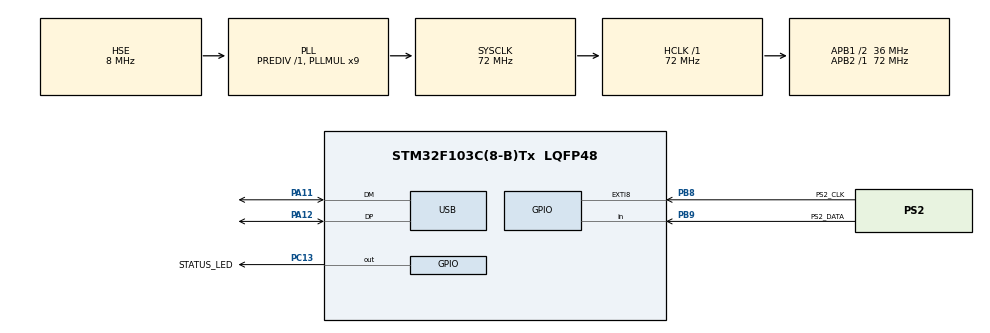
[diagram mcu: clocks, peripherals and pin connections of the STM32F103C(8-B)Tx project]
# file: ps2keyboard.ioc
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FREERTOS.Tasks01=defaultTask,0,128,StartDefaultTask,Default,NULL
FREERTOS.configUSE_COUNTING_SEMAPHORES=1
Mcu.Family=STM32F1
Mcu.Name=STM32F103C(8-B)Tx
Mcu.Package=LQFP48
NVIC.EXTI9_5_IRQn=true\:3\:0\:true\:false\:true\:false\:true
NVIC.PriorityGroup=NVIC_PRIORITYGROUP_4
NVIC.TIM1_UP_IRQn=true\:0\:0\:false\:false\:true\:false\:false
NVIC.TimeBase=TIM1_UP_IRQn
NVIC.TimeBaseIP=TIM1
NVIC.USB_LP_CAN1_RX0_IRQn=true\:5\:0\:false\:false\:true\:true\:false
PA11.Mode=Device
PA11.Signal=USB_DM
PA12.Mode=Device
PA12.Signal=USB_DP
PA13.Mode=Trace_Asynchronous_SW
PA13.Signal=SYS_JTMS-SWDIO
PA14.Mode=Trace_Asynchronous_SW
PA14.Signal=SYS_JTCK-SWCLK
PB3.Mode=Trace_Asynchronous_SW
PB3.Signal=SYS_JTDO-TRACESWO
PB8.GPIO_Label=PS2_CLK
PB8.GPIO_ModeDefaultEXTI=GPIO_MODE_IT_RISING
PB8.Signal=GPXTI8
PB9.GPIO_Label=PS2_DATA
PB9.Signal=GPIO_Input
PC13-TAMPER-RTC.GPIO_Label=STATUS_LED
PC13-TAMPER-RTC.Signal=GPIO_Output
PD0-OSC_IN.Mode=HSE-External-Oscillator
PD0-OSC_IN.Signal=RCC_OSC_IN
PD1-OSC_OUT.Mode=HSE-External-Oscillator
PD1-OSC_OUT.Signal=RCC_OSC_OUT
ProjectManager.HeapSize=0x200
ProjectManager.StackSize=0x400
ProjectManager.TargetToolchain=TrueSTUDIO
RCC.AHBFreq_Value=72000000
RCC.APB1CLKDivider=RCC_HCLK_DIV2
RCC.APB1Freq_Value=36000000
RCC.APB1TimFreq_Value=72000000
RCC.APB2Freq_Value=72000000
RCC.APB2TimFreq_Value=72000000
RCC.EnbaleCSS=true
RCC.HCLKFreq_Value=72000000
RCC.PLLMUL=RCC_PLL_MUL9
RCC.PLLSourceVirtual=RCC_PLLSOURCE_HSE
RCC.SYSCLKFreq_VALUE=72000000
RCC.SYSCLKSource=RCC_SYSCLKSOURCE_PLLCLK
RCC.USBFreq_Value=48000000
RCC.USBPrescaler=RCC_USBCLKSOURCE_PLL_DIV1_5
USB_DEVICE.CLASS_NAME_FS=CDC
USB_DEVICE.VirtualMode=Cdc
USB_DEVICE.VirtualModeFS=Cdc_FS
VP_FREERTOS_VS_ENABLE.Mode=Enabled
VP_SYS_VS_tim1.Mode=TIM1
VP_USB_DEVICE_VS_USB_DEVICE_CDC_FS.Mode=CDC_FS
board=ps2keyboard

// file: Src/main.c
/* USER CODE BEGIN Header */
/**
  * @brief  Function implementing the defaultTask thread.
  * @param  argument: Not used
  * @retval None
  */
/* USER CODE END Header */

#include "main.h"
#include "cmsis_os.h"
#include "usb_device.h"

/* USER CODE BEGIN Includes */
#include "tasks/startup.h"
/* USER CODE END Includes */

osThreadId defaultTaskHandle;
/* USER CODE BEGIN PV */
/* Private variables ---------------------------------------------------------*/

/* USER CODE END PV */

void SystemClock_Config(void);
static void MX_GPIO_Init(void);
void StartDefaultTask(void const * argument);

/* USER CODE BEGIN PFP */
/* Private function prototypes -----------------------------------------------*/

/* USER CODE END PFP */

/* USER CODE BEGIN 0 */
int _write(int32_t file, uint8_t *ptr, int32_t len) {
	for (int i=0; i<len; i++) {
		ITM_SendChar(ptr[i]);
	}
	return len;
}
/* USER CODE END 0 */

int main(void)
{

  /* MCU Configuration--------------------------------------------------------*/

  /* Reset of all peripherals, Initializes the Flash interface and the Systick. */
  HAL_Init();

  /* Configure the system clock */
  SystemClock_Config();

  /* Initialize all configured peripherals */
  MX_GPIO_Init();
  /* USER CODE BEGIN 2 */

  printf("Hello world\n");

  /* USER CODE END 2 */

  /* Create the thread(s) */
  /* definition and creation of defaultTask */
  osThreadDef(defaultTask, StartDefaultTask, osPriorityNormal, 0, 128);
  defaultTaskHandle = osThreadCreate(osThread(defaultTask), NULL);

  /* USER CODE BEGIN RTOS_THREADS */
  tasksStartup();
  /* USER CODE END RTOS_THREADS */

  /* Start scheduler */
  osKernelStart();

  /* We should never get here as control is now taken by the scheduler */

  /* Infinite loop */
  while (1)
  {

  }
}

void SystemClock_Config(void)
{
  RCC_OscInitTypeDef RCC_OscInitStruct = {0};
  RCC_ClkInitTypeDef RCC_ClkInitStruct = {0};
  RCC_PeriphCLKInitTypeDef PeriphClkInit = {0};

  /**Initializes the CPU, AHB and APB busses clocks
  */
  RCC_OscInitStruct.OscillatorType = RCC_OSCILLATORTYPE_HSE;
  RCC_OscInitStruct.HSEState = RCC_HSE_ON;
  RCC_OscInitStruct.HSEPredivValue = RCC_HSE_PREDIV_DIV1;
  RCC_OscInitStruct.HSIState = RCC_HSI_ON;
  RCC_OscInitStruct.PLL.PLLState = RCC_PLL_ON;
  RCC_OscInitStruct.PLL.PLLSource = RCC_PLLSOURCE_HSE;
  RCC_OscInitStruct.PLL.PLLMUL = RCC_PLL_MUL9;
  if (HAL_RCC_OscConfig(&RCC_OscInitStruct) != HAL_OK)
  {
    Error_Handler();
  }
  /**Initializes the CPU, AHB and APB busses clocks
  */
  RCC_ClkInitStruct.ClockType = RCC_CLOCKTYPE_HCLK|RCC_CLOCKTYPE_SYSCLK
                              |RCC_CLOCKTYPE_PCLK1|RCC_CLOCKTYPE_PCLK2;
  RCC_ClkInitStruct.SYSCLKSource = RCC_SYSCLKSOURCE_PLLCLK;
  RCC_ClkInitStruct.AHBCLKDivider = RCC_SYSCLK_DIV1;
  RCC_ClkInitStruct.APB1CLKDivider = RCC_HCLK_DIV2;
  RCC_ClkInitStruct.APB2CLKDivider = RCC_HCLK_DIV1;

  if (HAL_RCC_ClockConfig(&RCC_ClkInitStruct, FLASH_LATENCY_2) != HAL_OK)
  {
    Error_Handler();
  }
  PeriphClkInit.PeriphClockSelection = RCC_PERIPHCLK_USB;
  PeriphClkInit.UsbClockSelection = RCC_USBCLKSOURCE_PLL_DIV1_5;
  if (HAL_RCCEx_PeriphCLKConfig(&PeriphClkInit) != HAL_OK)
  {
    Error_Handler();
  }
  /**Enables the Clock Security System
  */
  HAL_RCC_EnableCSS();
}

static void MX_GPIO_Init(void)
{
  GPIO_InitTypeDef GPIO_InitStruct = {0};

  /* GPIO Ports Clock Enable */
  __HAL_RCC_GPIOC_CLK_ENABLE();
  __HAL_RCC_GPIOD_CLK_ENABLE();
  __HAL_RCC_GPIOA_CLK_ENABLE();
  __HAL_RCC_GPIOB_CLK_ENABLE();

  /*Configure GPIO pin Output Level */
  HAL_GPIO_WritePin(STATUS_LED_GPIO_Port, STATUS_LED_Pin, GPIO_PIN_RESET);

  /*Configure GPIO pin : STATUS_LED_Pin */
  GPIO_InitStruct.Pin = STATUS_LED_Pin;
  GPIO_InitStruct.Mode = GPIO_MODE_OUTPUT_PP;
  GPIO_InitStruct.Pull = GPIO_NOPULL;
  GPIO_InitStruct.Speed = GPIO_SPEED_FREQ_LOW;
  HAL_GPIO_Init(STATUS_LED_GPIO_Port, &GPIO_InitStruct);

  /*Configure GPIO pin : PS2_CLK_Pin */
  GPIO_InitStruct.Pin = PS2_CLK_Pin;
  GPIO_InitStruct.Mode = GPIO_MODE_IT_RISING;
  GPIO_InitStruct.Pull = GPIO_NOPULL;
  HAL_GPIO_Init(PS2_CLK_GPIO_Port, &GPIO_InitStruct);

  /*Configure GPIO pin : PS2_DATA_Pin */
  GPIO_InitStruct.Pin = PS2_DATA_Pin;
  GPIO_InitStruct.Mode = GPIO_MODE_INPUT;
  GPIO_InitStruct.Pull = GPIO_NOPULL;
  HAL_GPIO_Init(PS2_DATA_GPIO_Port, &GPIO_InitStruct);

  /* EXTI interrupt init*/
  HAL_NVIC_SetPriority(EXTI9_5_IRQn, 3, 0);
  HAL_NVIC_EnableIRQ(EXTI9_5_IRQn);

}

void StartDefaultTask(void const * argument)
{
  /* init code for USB_DEVICE */
  MX_USB_DEVICE_Init();

  for(;;)
  {
    osDelay(1);
  }
}

void HAL_TIM_PeriodElapsedCallback(TIM_HandleTypeDef *htim)
{
  if (htim->Instance == TIM1) {
    HAL_IncTick();
  }
}

void Error_Handler(void)
{
  while(1)
  {
  }
}

/************************ (C) COPYRIGHT STMicroelectronics *****END OF FILE****/
